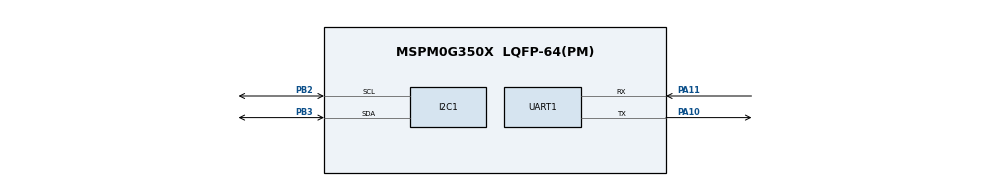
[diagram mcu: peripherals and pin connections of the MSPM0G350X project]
/**
 * @cliArgs --device "MSPM0G350X" --package "LQFP-64(PM)" --part "Default" --product "mspm0_sdk@2.01.00.03"
 * @versions {"tool":"1.20.0+3587"}
 */

/**
 * Import the modules used in this configuration.
 */
const GPIO   = scripting.addModule("/ti/driverlib/GPIO", {}, false);
const GPIO1  = GPIO.addInstance();
const I2C    = scripting.addModule("/ti/driverlib/I2C", {}, false);
const I2C1   = I2C.addInstance();
const QEI    = scripting.addModule("/ti/driverlib/QEI", {}, false);
const QEI1   = QEI.addInstance();
const SYSCTL = scripting.addModule("/ti/driverlib/SYSCTL");
const UART   = scripting.addModule("/ti/driverlib/UART", {}, false);
const UART1  = UART.addInstance();

/**
 * Write custom configuration values to the imported modules.
 */
const divider6       = system.clockTree["PLL_CLK2X_DIV"];
divider6.divideValue = 4;

const divider7       = system.clockTree["PLL_PDIV"];
divider7.divideValue = 2;

const divider9       = system.clockTree["UDIV"];
divider9.divideValue = 2;

const multiplier2         = system.clockTree["PLL_QDIV"];
multiplier2.multiplyValue = 10;

const mux8       = system.clockTree["HSCLKMUX"];
mux8.inputSelect = "HSCLKMUX_SYSPLL2X";

GPIO1.$name                          = "GPIO_OLED";
GPIO1.associatedPins.create(2);
GPIO1.associatedPins[0].$name        = "PIN_SCL";
GPIO1.associatedPins[0].assignedPort = "PORTA";
GPIO1.associatedPins[0].assignedPin  = "12";
GPIO1.associatedPins[1].$name        = "PIN_SDA";
GPIO1.associatedPins[1].assignedPort = "PORTA";
GPIO1.associatedPins[1].assignedPin  = "13";

const Board = scripting.addModule("/ti/driverlib/Board", {}, false);

I2C1.basicEnableController             = true;
I2C1.$name                             = "I2C_MPU6050";
I2C1.intController                     = ["ARBITRATION_LOST","NACK","RXFIFO_TRIGGER","RX_DONE","TX_DONE"];
I2C1.peripheral.$assign                = "I2C1";
I2C1.peripheral.sdaPin.$assign         = "PB3";
I2C1.peripheral.sclPin.$assign         = "PB2";
I2C1.sdaPinConfig.hideOutputInversion  = scripting.forceWrite(false);
I2C1.sdaPinConfig.onlyInternalResistor = scripting.forceWrite(false);
I2C1.sdaPinConfig.passedPeripheralType = scripting.forceWrite("Digital");
I2C1.sdaPinConfig.$name                = "ti_driverlib_gpio_GPIOPinGeneric2";
I2C1.sclPinConfig.hideOutputInversion  = scripting.forceWrite(false);
I2C1.sclPinConfig.onlyInternalResistor = scripting.forceWrite(false);
I2C1.sclPinConfig.passedPeripheralType = scripting.forceWrite("Digital");
I2C1.sclPinConfig.$name                = "ti_driverlib_gpio_GPIOPinGeneric3";

QEI1.$name               = "QEI_0";
QEI1.ccp0PinConfig.$name = "ti_driverlib_gpio_GPIOPinGeneric4";
QEI1.ccp1PinConfig.$name = "ti_driverlib_gpio_GPIOPinGeneric5";

SYSCTL.forceDefaultClkConfig = true;
SYSCTL.clockTreeEn           = true;

UART1.$name                    = "UART_0";
UART1.peripheral.rxPin.$assign = "PA11";
UART1.peripheral.txPin.$assign = "PA10";
UART1.txPinConfig.$name        = "ti_driverlib_gpio_GPIOPinGeneric0";
UART1.rxPinConfig.$name        = "ti_driverlib_gpio_GPIOPinGeneric1";

/**
 * Pinmux solution for unlocked pins/peripherals. This ensures that minor changes to the automatic solver in a future
 * version of the tool will not impact the pinmux you originally saw.  These lines can be completely deleted in order to
 * re-solve from scratch.
 */
GPIO1.associatedPins[0].pin.$suggestSolution = "PA12";
GPIO1.associatedPins[1].pin.$suggestSolution = "PA13";
Board.peripheral.$suggestSolution            = "DEBUGSS";
Board.peripheral.swclkPin.$suggestSolution   = "PA20";
Board.peripheral.swdioPin.$suggestSolution   = "PA19";
QEI1.peripheral.$suggestSolution             = "TIMG8";
QEI1.peripheral.ccp0Pin.$suggestSolution     = "PA1";
QEI1.peripheral.ccp1Pin.$suggestSolution     = "PA0";
UART1.peripheral.$suggestSolution            = "UART0";
